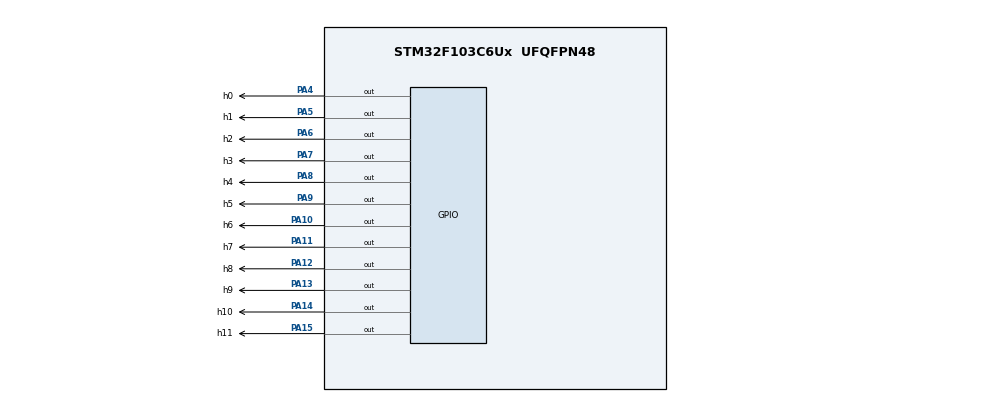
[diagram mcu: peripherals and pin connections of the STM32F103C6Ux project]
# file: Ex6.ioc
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Mcu.Family=STM32F1
Mcu.Name=STM32F103C6Ux
Mcu.Package=UFQFPN48
NVIC.PriorityGroup=NVIC_PRIORITYGROUP_4
PA10.GPIO_Label=h6
PA10.GPIO_ModeDefaultOutputPP=GPIO_MODE_OUTPUT_PP
PA10.PinState=GPIO_PIN_SET
PA10.Signal=GPIO_Output
PA11.GPIO_Label=h7
PA11.GPIO_ModeDefaultOutputPP=GPIO_MODE_OUTPUT_PP
PA11.PinState=GPIO_PIN_SET
PA11.Signal=GPIO_Output
PA12.GPIO_Label=h8
PA12.GPIO_ModeDefaultOutputPP=GPIO_MODE_OUTPUT_PP
PA12.PinState=GPIO_PIN_SET
PA12.Signal=GPIO_Output
PA13.GPIO_Label=h9
PA13.GPIO_ModeDefaultOutputPP=GPIO_MODE_OUTPUT_PP
PA13.PinState=GPIO_PIN_SET
PA13.Signal=GPIO_Output
PA14.GPIO_Label=h10
PA14.GPIO_ModeDefaultOutputPP=GPIO_MODE_OUTPUT_PP
PA14.PinState=GPIO_PIN_SET
PA14.Signal=GPIO_Output
PA15.GPIO_Label=h11
PA15.GPIO_ModeDefaultOutputPP=GPIO_MODE_OUTPUT_PP
PA15.PinState=GPIO_PIN_SET
PA15.Signal=GPIO_Output
PA4.GPIO_Label=h0
PA4.GPIO_ModeDefaultOutputPP=GPIO_MODE_OUTPUT_PP
PA4.PinState=GPIO_PIN_SET
PA4.Signal=GPIO_Output
PA5.GPIO_Label=h1
PA5.GPIO_ModeDefaultOutputPP=GPIO_MODE_OUTPUT_PP
PA5.PinState=GPIO_PIN_SET
PA5.Signal=GPIO_Output
PA6.GPIO_Label=h2
PA6.GPIO_ModeDefaultOutputPP=GPIO_MODE_OUTPUT_PP
PA6.PinState=GPIO_PIN_SET
PA6.Signal=GPIO_Output
PA7.GPIO_Label=h3
PA7.GPIO_ModeDefaultOutputPP=GPIO_MODE_OUTPUT_PP
PA7.PinState=GPIO_PIN_SET
PA7.Signal=GPIO_Output
PA8.GPIO_Label=h4
PA8.GPIO_ModeDefaultOutputPP=GPIO_MODE_OUTPUT_PP
PA8.PinState=GPIO_PIN_SET
PA8.Signal=GPIO_Output
PA9.GPIO_Label=h5
PA9.GPIO_ModeDefaultOutputPP=GPIO_MODE_OUTPUT_PP
PA9.PinState=GPIO_PIN_SET
PA9.Signal=GPIO_Output
ProjectManager.HeapSize=0x200
ProjectManager.StackSize=0x400
ProjectManager.TargetToolchain=STM32CubeIDE
RCC.APB1Freq_Value=8000000
RCC.APB2Freq_Value=8000000
VP_SYS_VS_ND.Mode=No_Debug
board=custom

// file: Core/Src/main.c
/* USER CODE BEGIN Header */
/**
  ******************************************************************************
  * @file           : main.c
  * @brief          : Main program body
  ******************************************************************************
  * @attention
  *
  * Copyright (c) 2026 STMicroelectronics.
  * All rights reserved.
  *
  * This software is licensed under terms that can be found in the LICENSE file
  * in the root directory of this software component.
  * If no LICENSE file comes with this software, it is provided AS-IS.
  *
  ******************************************************************************
  */
/* USER CODE END Header */
#include "main.h"

void SystemClock_Config(void);
static void MX_GPIO_Init(void);

/* USER CODE BEGIN 0 */
void clearAllClockLEDs(void) {
    for (uint32_t pin = GPIO_PIN_4; pin <= GPIO_PIN_15; pin <<= 1) {
        HAL_GPIO_WritePin(GPIOA, (uint16_t)pin, GPIO_PIN_SET);
    }
}
/* USER CODE END 0 */

int main(void)
{

  /* MCU Configuration--------------------------------------------------------*/

  /* Reset of all peripherals, Initializes the Flash interface and the Systick. */
  HAL_Init();

  /* Configure the system clock */
  SystemClock_Config();

  /* Initialize all configured peripherals */
  MX_GPIO_Init();

  /* Infinite loop */
  /* USER CODE BEGIN WHILE */
  while (1)
  {
	  for (int i = 4; i <= 15; i++) {
		clearAllClockLEDs();

		HAL_GPIO_WritePin(GPIOA, (uint16_t)(1 << i), GPIO_PIN_RESET);

		HAL_Delay(1000);
		}
    /* USER CODE END WHILE */

  }
}

void SystemClock_Config(void)
{
  RCC_OscInitTypeDef RCC_OscInitStruct = {0};
  RCC_ClkInitTypeDef RCC_ClkInitStruct = {0};

  /** Initializes the RCC Oscillators according to the specified parameters
  * in the RCC_OscInitTypeDef structure.
  */
  RCC_OscInitStruct.OscillatorType = RCC_OSCILLATORTYPE_HSI;
  RCC_OscInitStruct.HSIState = RCC_HSI_ON;
  RCC_OscInitStruct.HSICalibrationValue = RCC_HSICALIBRATION_DEFAULT;
  RCC_OscInitStruct.PLL.PLLState = RCC_PLL_NONE;
  if (HAL_RCC_OscConfig(&RCC_OscInitStruct) != HAL_OK)
  {
    Error_Handler();
  }

  /** Initializes the CPU, AHB and APB buses clocks
  */
  RCC_ClkInitStruct.ClockType = RCC_CLOCKTYPE_HCLK|RCC_CLOCKTYPE_SYSCLK
                              |RCC_CLOCKTYPE_PCLK1|RCC_CLOCKTYPE_PCLK2;
  RCC_ClkInitStruct.SYSCLKSource = RCC_SYSCLKSOURCE_HSI;
  RCC_ClkInitStruct.AHBCLKDivider = RCC_SYSCLK_DIV1;
  RCC_ClkInitStruct.APB1CLKDivider = RCC_HCLK_DIV1;
  RCC_ClkInitStruct.APB2CLKDivider = RCC_HCLK_DIV1;

  if (HAL_RCC_ClockConfig(&RCC_ClkInitStruct, FLASH_LATENCY_0) != HAL_OK)
  {
    Error_Handler();
  }
}

static void MX_GPIO_Init(void)
{
  GPIO_InitTypeDef GPIO_InitStruct = {0};

  /* GPIO Ports Clock Enable */
  __HAL_RCC_GPIOA_CLK_ENABLE();

  /*Configure GPIO pin Output Level */
  HAL_GPIO_WritePin(GPIOA, h0_Pin|h1_Pin|h2_Pin|h3_Pin
                          |h4_Pin|h5_Pin|h6_Pin|h7_Pin
                          |h8_Pin|h9_Pin|h10_Pin|h11_Pin, GPIO_PIN_SET);

  /*Configure GPIO pins : h0_Pin h1_Pin h2_Pin h3_Pin
                           h4_Pin h5_Pin h6_Pin h7_Pin
                           h8_Pin h9_Pin h10_Pin h11_Pin */
  GPIO_InitStruct.Pin = h0_Pin|h1_Pin|h2_Pin|h3_Pin
                          |h4_Pin|h5_Pin|h6_Pin|h7_Pin
                          |h8_Pin|h9_Pin|h10_Pin|h11_Pin;
  GPIO_InitStruct.Mode = GPIO_MODE_OUTPUT_PP;
  GPIO_InitStruct.Pull = GPIO_NOPULL;
  GPIO_InitStruct.Speed = GPIO_SPEED_FREQ_LOW;
  HAL_GPIO_Init(GPIOA, &GPIO_InitStruct);

}

void Error_Handler(void)
{
  __disable_irq();
  while (1)
  {
  }
}
